# BlueNRG_LPS register map
File version: 1.0
CPU: CM0+ r0p0, little endian, no MPU, no FPU, 2 interrupt priority bits
Registers are 32-bit, read-write, reset 0x0 unless marked. A register's access mark holds for its fields unless they carry their own. Offsets are from the block's base; [hi:lo] are bit positions; {n}, {i} and the like mark numbered series.

## PWR — Power control
Base 0x48500000
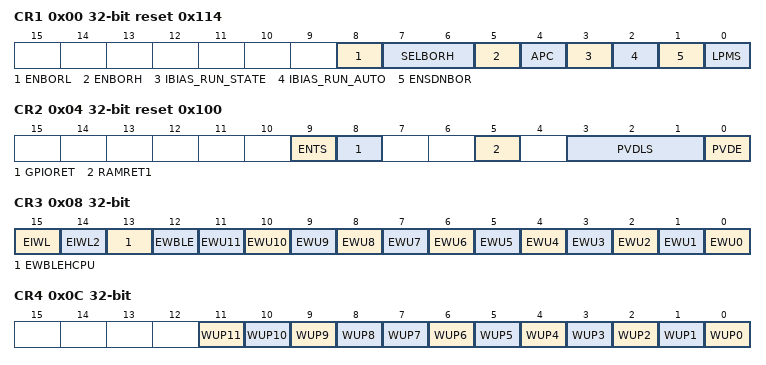
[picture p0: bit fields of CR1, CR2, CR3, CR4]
0x00 CR1 reset 0x114 — Power control register 1
  [8] ENBORL — Enable BORL reset supervising during RUN mode.
  [7:6] SELBORH — BORH voltage threshold selection:
  [5] ENBORH — Enable the BORH software configuration.
  [4] APC — Apply pull-up/-down configuration from PWRC or GPIO register.
  [3] IBIAS_RUN_STATE — Enable/Disable IBIAs during RUN mode when automatic mode is
  [2] IBIAS_RUN_AUTO — Enable automatic IBIAs control during RUN/DEEPSTOP mode.
  [1] ENSDNBOR — Enable BOR reset supervising during SHUTDOWN mode.
  [0] LPMS — Low Power Mode Selection.
0x04 CR2 reset 0x100 — Power control register 2
  [9] ENTS — Enable Temperature Sensor
  [8] GPIORET — GPIO retention enable.
  [5] RAMRET1 — RAM1 retention during low power mode
  [3:1] PVDLS — Programmable Voltage Detector Level selection
  [0] PVDE — Programmable Voltage Detector Enable
0x08 CR3 — Power control register 3
  [15] EIWL — Enable wakeup on Internal event (RTC).
  [14] EIWL2 — Enable wakeup on Internal event (LPUART).
  [13] EWBLEHCPU — EWBLEHCPU Wakeup BLE Host CPU Enable
  [12] EWBLE — Wakeup BLE Enable
  [n] EWU{n} (n=0..11) — Enable WakeUp line {n}
0x0C CR4 — Power control register 4
  [11] WUP11 — Wakeup polarity for PA11 I/O.
  [10] WUP10 — Wakeup polarity for PA10 I/O.
  [9] WUP9 — Wakeup polarity for PA9 IO event.
  [8] WUP8 — Wakeup polarity for PA8 IO event.
  [n] WUP{n} (n=0..7) — Wakeup polarity for PB{n} IO event.
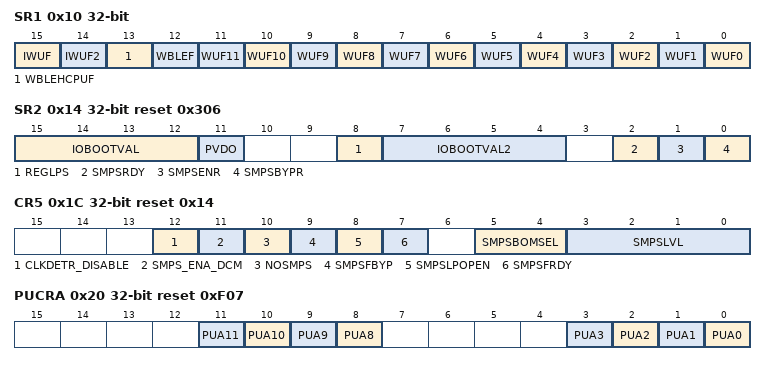
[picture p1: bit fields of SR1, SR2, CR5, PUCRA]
0x10 SR1 — Power status register 1
  [15] IWUF — Internal wakeup flag (RTC).
  [14] IWUF2 — Internal wakeup 2 flag (LPUART).
  [13] WBLEHCPUF — Wakeup BLE HOST CPU Flag (cf. user manual)
  [12] WBLEF — Wakeup BLE Flag
  [n] WUF{n} (n=0..11) — WakeUp Flag {n}
0x14 SR2 ro reset 0x306 — Power status register 2
  [15:12] IOBOOTVAL
  [11] PVDO — Power Voltage Detector Output
  [8] REGLPS — Regulator Low Power Started
  [7:4] IOBOOTVAL2 — I/Os value latched at POR.
  [2] SMPSRDY — SMPs Ready Status
  [1] SMPSENR — SMPs Enable Control Replica
  [0] SMPSBYPR — SMPs Force Bypass Control Replica
0x1C CR5 reset 0x14 — Power control register 5
  [12] CLKDETR_DISABLE — disable the SMPs clock detection
  [11] SMPS_ENA_DCM — Discontinuous conduction mode enable.
  [10] NOSMPS — No SMPs Mode
  [9] SMPSFBYP — Force SMPs Regulator in bypass mode
  [8] SMPSLPOPEN — In Low Power mode SMPs is in OPEN mode (instead of PRECHARGE mode).
  [7] SMPSFRDY — Force ready check
  [5:4] SMPSBOMSEL — SMPs BOM Selection
  [3:0] SMPSLVL — SMPs Output Level Voltage Selection
0x20 PUCRA reset 0xF07 — Power Port A pull-up control register
  [n] PUA{n} (n=8..11) — Port A PAll-up bit {n}
  [n] PUA{n} (n=0..3) — Port A PAll-up bit {n}
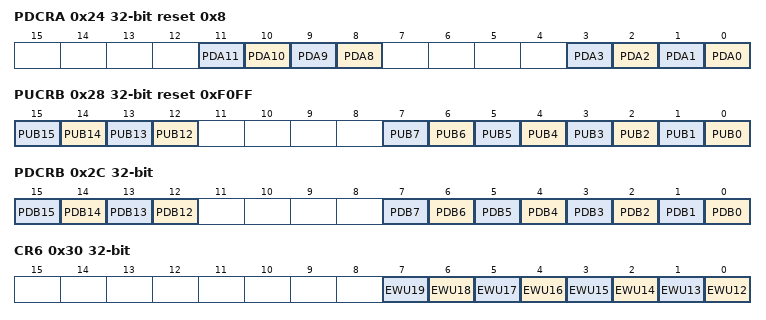
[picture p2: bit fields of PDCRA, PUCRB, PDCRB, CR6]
0x24 PDCRA reset 0x8 — Power Port A pull-down control register
  [n] PDA{n} (n=8..11) — Port A pull-down bit {n}
  [n] PDA{n} (n=0..3) — Port A pull-down bit {n}
0x28 PUCRB reset 0xF0FF — Power Port B pull-up control register
  [n] PUB{n} (n=12..15) — Port B PBll-up bit {n}
  [n] PUB{n} (n=0..7) — Port B PBll-up bit {n}
0x2C PDCRB — Power Port B pull-down control register
  [n] PDB{n} (n=12..15) — Port B pull-down bit {n}
  [n] PDB{n} (n=0..7) — Port B pull-down bit {n}
0x30 CR6 — This register manages the selection of the wakeup sources to get out of DEEPSTOP mode
  [n-12] EWU{n} (n=12..19) — Enable wakeup on PA{n-12} I/O event.
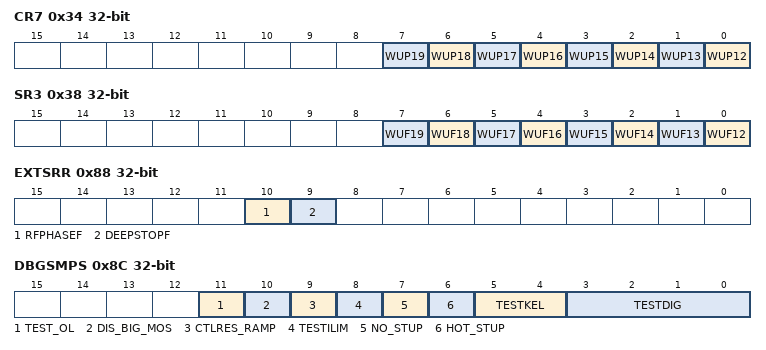
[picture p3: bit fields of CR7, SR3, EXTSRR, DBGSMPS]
0x34 CR7 — This register manages the polarity for the I/Os wakeup sources to get out of DEEPSTOP
  [n-12] WUP{n} (n=12..19) — Wakeup polarity for PA{n-12} IO event.
0x38 SR3 — This register provides the information concerning which source woke up the device after a DEEPSTOP.
  [n-12] WUF{n} (n=12..19) — PA{n-12} I/O wakeup flag.
0x84 DBGR — This register is used for debug features
  [0] DEEPSTOP2 — DEEPSTOP2 low power saving emulation enable.
0x88 EXTSRR — Power status clear register
  [10] RFPHASEF — RFPHAs Flag
  [9] DEEPSTOPF — System DeepStop Flag
0x8C DBGSMPS — This register drives some control signals for the SMPS
  [11] TEST_OL — TEST_OL_3V3 SMPs control signal.
  [10] DIS_BIG_MOS — DIS_BIG_MOS_3V3 SMPs control signal.
  [9] CTLRES_RAMP — CTLRES_RAMP_3V3 SMPs control signal.
  [8] TESTILIM — SMPS_TEST_ILIM_3V3 control signal.
  [7] NO_STUP — NO_STUP_3V3 SMPs control signal.
  [6] HOT_STUP — HOT_STUP_3V3 SMPs control signal.
  [5:4] TESTKEL — SMPS_TEST_KEL_3V3[2:0] control bus.
  [3:0] TESTDIG — SMPS_TEST_DIG_3V3[3:0] control bus.
